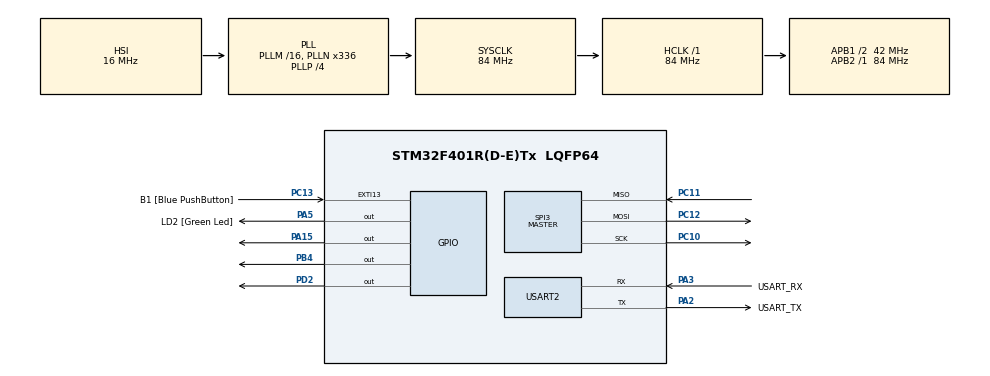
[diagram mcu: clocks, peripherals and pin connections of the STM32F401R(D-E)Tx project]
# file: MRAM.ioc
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Mcu.Family=STM32F4
Mcu.Name=STM32F401R(D-E)Tx
Mcu.Package=LQFP64
NVIC.PriorityGroup=NVIC_PRIORITYGROUP_0
PA13.GPIO_Label=TMS
PA13.Signal=SYS_JTMS-SWDIO
PA14.GPIO_Label=TCK
PA14.Signal=SYS_JTCK-SWCLK
PA15.Signal=GPIO_Output
PA2.GPIO_Label=USART_TX
PA2.GPIO_Mode=GPIO_MODE_AF_PP
PA2.GPIO_PuPd=GPIO_NOPULL
PA2.GPIO_Speed=GPIO_SPEED_FREQ_LOW
PA2.Mode=Asynchronous
PA2.Signal=USART2_TX
PA3.GPIO_Label=USART_RX
PA3.GPIO_Mode=GPIO_MODE_AF_PP
PA3.GPIO_PuPd=GPIO_NOPULL
PA3.GPIO_Speed=GPIO_SPEED_FREQ_LOW
PA3.Mode=Asynchronous
PA3.Signal=USART2_RX
PA5.GPIO_Label=LD2 [Green Led]
PA5.GPIO_Mode=GPIO_MODE_OUTPUT_PP
PA5.GPIO_PuPd=GPIO_NOPULL
PA5.GPIO_Speed=GPIO_SPEED_FREQ_LOW
PA5.Signal=GPIO_Output
PB3.GPIO_Label=SWO
PB3.Signal=SYS_JTDO-SWO
PB4.Signal=GPIO_Output
PC10.Mode=Full_Duplex_Master
PC10.Signal=SPI3_SCK
PC11.Mode=Full_Duplex_Master
PC11.Signal=SPI3_MISO
PC12.Mode=Full_Duplex_Master
PC12.Signal=SPI3_MOSI
PC13-ANTI_TAMP.GPIO_Label=B1 [Blue PushButton]
PC13-ANTI_TAMP.GPIO_ModeDefaultEXTI=GPIO_MODE_IT_FALLING
PC13-ANTI_TAMP.GPIO_PuPd=GPIO_NOPULL
PC13-ANTI_TAMP.Signal=GPXTI13
PC14-OSC32_IN.Signal=RCC_OSC32_IN
PC15-OSC32_OUT.Signal=RCC_OSC32_OUT
PD2.Signal=GPIO_Output
PH0\ -\ OSC_IN.Signal=RCC_OSC_IN
PH1\ -\ OSC_OUT.Signal=RCC_OSC_OUT
ProjectManager.HeapSize=0x200
ProjectManager.StackSize=0x400
ProjectManager.TargetToolchain=SW4STM32
RCC.AHBFreq_Value=84000000
RCC.APB1CLKDivider=RCC_HCLK_DIV2
RCC.APB1Freq_Value=42000000
RCC.APB1TimFreq_Value=84000000
RCC.APB2Freq_Value=84000000
RCC.APB2TimFreq_Value=84000000
RCC.CortexFreq_Value=84000000
RCC.HCLKFreq_Value=84000000
RCC.HSE_VALUE=8000000
RCC.HSI_VALUE=16000000
RCC.LSE_VALUE=32768
RCC.PLLN=336
RCC.PLLP=RCC_PLLP_DIV4
RCC.PLLQ=7
RCC.SYSCLKFreq_VALUE=84000000
RCC.SYSCLKSource=RCC_SYSCLKSOURCE_PLLCLK
RCC.VCOOutputFreq_Value=336000000
SPI3.Direction=SPI_DIRECTION_2LINES
SPI3.Mode=SPI_MODE_MASTER
SPI3.VirtualType=VM_MASTER
USART2.VirtualMode=VM_ASYNC
board=NUCLEO-F401RE

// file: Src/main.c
/**
  ******************************************************************************
  * File Name          : main.c
  * Description        : Main program body
  ******************************************************************************
  ** This notice applies to any and all portions of this file
  * that are not between comment pairs USER CODE BEGIN and
  * USER CODE END. Other portions of this file, whether
  * inserted by the user or by software development tools
  * are owned by their respective copyright owners.
  *
  * COPYRIGHT(c) 2018 STMicroelectronics
  *
  * Redistribution and use in source and binary forms, with or without modification,
  * are permitted provided that the following conditions are met:
  *   1. Redistributions of source code must retain the above copyright notice,
  *      this list of conditions and the following disclaimer.
  *   2. Redistributions in binary form must reproduce the above copyright notice,
  *      this list of conditions and the following disclaimer in the documentation
  *      and/or other materials provided with the distribution.
  *   3. Neither the name of STMicroelectronics nor the names of its contributors
  *      may be used to endorse or promote products derived from this software
  *      without specific prior written permission.
  *
  * THIS SOFTWARE IS PROVIDED BY THE COPYRIGHT HOLDERS AND CONTRIBUTORS "AS IS"
  * AND ANY EXPRESS OR IMPLIED WARRANTIES, INCLUDING, BUT NOT LIMITED TO, THE
  * IMPLIED WARRANTIES OF MERCHANTABILITY AND FITNESS FOR A PARTICULAR PURPOSE ARE
  * DISCLAIMED. IN NO EVENT SHALL THE COPYRIGHT HOLDER OR CONTRIBUTORS BE LIABLE
  * FOR ANY DIRECT, INDIRECT, INCIDENTAL, SPECIAL, EXEMPLARY, OR CONSEQUENTIAL
  * DAMAGES (INCLUDING, BUT NOT LIMITED TO, PROCUREMENT OF SUBSTITUTE GOODS OR
  * SERVICES; LOSS OF USE, DATA, OR PROFITS; OR BUSINESS INTERRUPTION) HOWEVER
  * CAUSED AND ON ANY THEORY OF LIABILITY, WHETHER IN CONTRACT, STRICT LIABILITY,
  * OR TORT (INCLUDING NEGLIGENCE OR OTHERWISE) ARISING IN ANY WAY OUT OF THE USE
  * OF THIS SOFTWARE, EVEN IF ADVISED OF THE POSSIBILITY OF SUCH DAMAGE.
  *
  ******************************************************************************
  */
#include "main.h"
#include "stm32f4xx_hal.h"
#include "MRAM.h"

SPI_HandleTypeDef hspi3;

UART_HandleTypeDef huart2;

/* USER CODE BEGIN PV */
/* Private variables ---------------------------------------------------------*/

/* USER CODE END PV */

void SystemClock_Config(void);
static void MX_GPIO_Init(void);
static void MX_SPI3_Init(void);
static void MX_USART2_UART_Init(void);

/* USER CODE BEGIN PFP */
/* Private function prototypes -----------------------------------------------*/

/* USER CODE END PFP */

int main(void)
{

  /* MCU Configuration----------------------------------------------------------*/

  /* Reset of all peripherals, Initializes the Flash interface and the Systick. */
  HAL_Init();

  /* Configure the system clock */
  SystemClock_Config();

  /* Initialize all configured peripherals */
  MX_GPIO_Init();
  MX_SPI3_Init();
  MX_USART2_UART_Init();

  /* USER CODE BEGIN 2 */
  uint8_t status;
  uint8_t *init = "INITIALIZED\n";
  uint8_t *data_write = "SOMEDATA";
  uint8_t *data_read = 0;
  uint16_t address = 0x100;

  //HAL_UART_Transmit(&huart2, init, 12, 50);

  write_enable(1);
  write_status(0x8E);
  read_status(status);
  status = status + '0';
  //write_mem(address, 8, data_write);
  //read_mem(address, 8, data_read);
  HAL_UART_Transmit(&huart2, &status, 1, 50);
  HAL_UART_Transmit(&huart2, init, 12, 50);

  /* USER CODE END 2 */

  /* Infinite loop */
  while (1)
  {

  }

}

/** System Clock Configuration
*/
void SystemClock_Config(void)
{

  RCC_OscInitTypeDef RCC_OscInitStruct;
  RCC_ClkInitTypeDef RCC_ClkInitStruct;

    /**Configure the main internal regulator output voltage
    */
  __HAL_RCC_PWR_CLK_ENABLE();

  __HAL_PWR_VOLTAGESCALING_CONFIG(PWR_REGULATOR_VOLTAGE_SCALE2);

    /**Initializes the CPU, AHB and APB busses clocks
    */
  RCC_OscInitStruct.OscillatorType = RCC_OSCILLATORTYPE_HSI;
  RCC_OscInitStruct.HSIState = RCC_HSI_ON;
  RCC_OscInitStruct.HSICalibrationValue = 16;
  RCC_OscInitStruct.PLL.PLLState = RCC_PLL_ON;
  RCC_OscInitStruct.PLL.PLLSource = RCC_PLLSOURCE_HSI;
  RCC_OscInitStruct.PLL.PLLM = 16;
  RCC_OscInitStruct.PLL.PLLN = 336;
  RCC_OscInitStruct.PLL.PLLP = RCC_PLLP_DIV4;
  RCC_OscInitStruct.PLL.PLLQ = 7;
  if (HAL_RCC_OscConfig(&RCC_OscInitStruct) != HAL_OK)
  {
    _Error_Handler(__FILE__, __LINE__);
  }

    /**Initializes the CPU, AHB and APB busses clocks
    */
  RCC_ClkInitStruct.ClockType = RCC_CLOCKTYPE_HCLK|RCC_CLOCKTYPE_SYSCLK
                              |RCC_CLOCKTYPE_PCLK1|RCC_CLOCKTYPE_PCLK2;
  RCC_ClkInitStruct.SYSCLKSource = RCC_SYSCLKSOURCE_PLLCLK;
  RCC_ClkInitStruct.AHBCLKDivider = RCC_SYSCLK_DIV1;
  RCC_ClkInitStruct.APB1CLKDivider = RCC_HCLK_DIV2;
  RCC_ClkInitStruct.APB2CLKDivider = RCC_HCLK_DIV1;

  if (HAL_RCC_ClockConfig(&RCC_ClkInitStruct, FLASH_LATENCY_2) != HAL_OK)
  {
    _Error_Handler(__FILE__, __LINE__);
  }

    /**Configure the Systick interrupt time
    */
  HAL_SYSTICK_Config(HAL_RCC_GetHCLKFreq()/1000);

    /**Configure the Systick
    */
  HAL_SYSTICK_CLKSourceConfig(SYSTICK_CLKSOURCE_HCLK);

  /* SysTick_IRQn interrupt configuration */
  HAL_NVIC_SetPriority(SysTick_IRQn, 0, 0);
}

/* SPI3 init function */
static void MX_SPI3_Init(void)
{

  hspi3.Instance = SPI3;
  hspi3.Init.Mode = SPI_MODE_MASTER;
  hspi3.Init.Direction = SPI_DIRECTION_2LINES;
  hspi3.Init.DataSize = SPI_DATASIZE_8BIT;
  hspi3.Init.CLKPolarity = SPI_POLARITY_LOW;
  hspi3.Init.CLKPhase = SPI_PHASE_1EDGE;
  hspi3.Init.NSS = SPI_NSS_SOFT;
  hspi3.Init.BaudRatePrescaler = SPI_BAUDRATEPRESCALER_2;
  hspi3.Init.FirstBit = SPI_FIRSTBIT_MSB;
  hspi3.Init.TIMode = SPI_TIMODE_DISABLE;
  hspi3.Init.CRCCalculation = SPI_CRCCALCULATION_DISABLE;
  hspi3.Init.CRCPolynomial = 10;
  if (HAL_SPI_Init(&hspi3) != HAL_OK)
  {
    _Error_Handler(__FILE__, __LINE__);
  }

}

/* USART2 init function */
static void MX_USART2_UART_Init(void)
{

  huart2.Instance = USART2;
  huart2.Init.BaudRate = 115200;
  huart2.Init.WordLength = UART_WORDLENGTH_8B;
  huart2.Init.StopBits = UART_STOPBITS_1;
  huart2.Init.Parity = UART_PARITY_NONE;
  huart2.Init.Mode = UART_MODE_TX_RX;
  huart2.Init.HwFlowCtl = UART_HWCONTROL_NONE;
  huart2.Init.OverSampling = UART_OVERSAMPLING_16;
  if (HAL_UART_Init(&huart2) != HAL_OK)
  {
    _Error_Handler(__FILE__, __LINE__);
  }

}

/** Configure pins as
        * Analog
        * Input
        * Output
        * EVENT_OUT
        * EXTI
*/
static void MX_GPIO_Init(void)
{

  GPIO_InitTypeDef GPIO_InitStruct;

  /* GPIO Ports Clock Enable */
  __HAL_RCC_GPIOC_CLK_ENABLE();
  __HAL_RCC_GPIOH_CLK_ENABLE();
  __HAL_RCC_GPIOA_CLK_ENABLE();
  __HAL_RCC_GPIOD_CLK_ENABLE();
  __HAL_RCC_GPIOB_CLK_ENABLE();

  /*Configure GPIO pin Output Level */
  HAL_GPIO_WritePin(GPIOA, LD2_Pin|GPIO_PIN_15, GPIO_PIN_SET);

  /*Configure GPIO pin Output Level */
  HAL_GPIO_WritePin(GPIOD, GPIO_PIN_2, GPIO_PIN_RESET);

  /*Configure GPIO pin Output Level */
  HAL_GPIO_WritePin(GPIOB, GPIO_PIN_4, GPIO_PIN_SET);

  /*Configure GPIO pin : B1_Pin */
  GPIO_InitStruct.Pin = B1_Pin;
  GPIO_InitStruct.Mode = GPIO_MODE_IT_FALLING;
  GPIO_InitStruct.Pull = GPIO_NOPULL;
  HAL_GPIO_Init(B1_GPIO_Port, &GPIO_InitStruct);

  /*Configure GPIO pins : LD2_Pin PA15 */
  GPIO_InitStruct.Pin = LD2_Pin|GPIO_PIN_15;
  GPIO_InitStruct.Mode = GPIO_MODE_OUTPUT_PP;
  GPIO_InitStruct.Pull = GPIO_NOPULL;
  GPIO_InitStruct.Speed = GPIO_SPEED_FREQ_LOW;
  HAL_GPIO_Init(GPIOA, &GPIO_InitStruct);

  /*Configure GPIO pin : PD2 */
  GPIO_InitStruct.Pin = GPIO_PIN_2;
  GPIO_InitStruct.Mode = GPIO_MODE_OUTPUT_PP;
  GPIO_InitStruct.Pull = GPIO_NOPULL;
  GPIO_InitStruct.Speed = GPIO_SPEED_FREQ_LOW;
  HAL_GPIO_Init(GPIOD, &GPIO_InitStruct);

  /*Configure GPIO pin : PB4 */
  GPIO_InitStruct.Pin = GPIO_PIN_4;
  GPIO_InitStruct.Mode = GPIO_MODE_OUTPUT_PP;
  GPIO_InitStruct.Pull = GPIO_NOPULL;
  GPIO_InitStruct.Speed = GPIO_SPEED_FREQ_LOW;
  HAL_GPIO_Init(GPIOB, &GPIO_InitStruct);

}

void _Error_Handler(char * file, int line)
{
  while(1)
  {
  }
}

/************************ (C) COPYRIGHT STMicroelectronics *****END OF FILE****/
